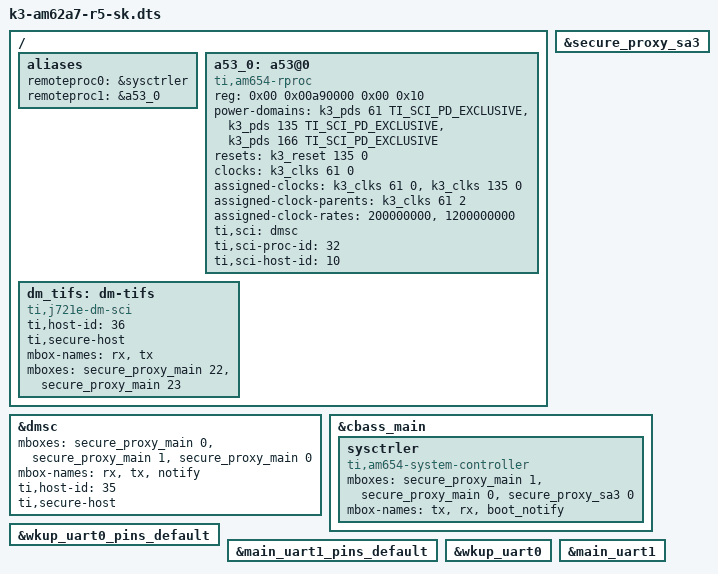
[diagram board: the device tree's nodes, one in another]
// SPDX-License-Identifier: GPL-2.0
/*
 * AM62A7 SK dts file for R5 SPL
 * Copyright (C) 2022 Texas Instruments Incorporated - https://www.ti.com/
 */

#include "k3-am62a7-sk.dts"
#include "k3-am62a-ddr-1866mhz-32bit.dtsi"
#include "k3-am62a-ddr.dtsi"

#include "k3-am62a7-sk-u-boot.dtsi"

/ {
	aliases {
		remoteproc0 = &sysctrler;
		remoteproc1 = &a53_0;
	};

	a53_0: a53@0 {
		compatible = "ti,am654-rproc";
		reg = <0x00 0x00a90000 0x00 0x10>;
		power-domains = <&k3_pds 61 TI_SCI_PD_EXCLUSIVE>,
				<&k3_pds 135 TI_SCI_PD_EXCLUSIVE>,
				<&k3_pds 166 TI_SCI_PD_EXCLUSIVE>;
		resets = <&k3_reset 135 0>;
		clocks = <&k3_clks 61 0>;
		assigned-clocks = <&k3_clks 61 0>, <&k3_clks 135 0>;
		assigned-clock-parents = <&k3_clks 61 2>;
		assigned-clock-rates = <200000000>, <1200000000>;
		ti,sci = <&dmsc>;
		ti,sci-proc-id = <32>;
		ti,sci-host-id = <10>;
		bootph-pre-ram;
	};

	dm_tifs: dm-tifs {
		compatible = "ti,j721e-dm-sci";
		ti,host-id = <36>;
		ti,secure-host;
		mbox-names = "rx", "tx";
		mboxes= <&secure_proxy_main 22>,
			<&secure_proxy_main 23>;
		bootph-pre-ram;
	};
};

&dmsc {
	mboxes= <&secure_proxy_main 0>,
		<&secure_proxy_main 1>,
		<&secure_proxy_main 0>;
	mbox-names = "rx", "tx", "notify";
	ti,host-id = <35>;
	ti,secure-host;
};

&secure_proxy_sa3 {
	/* Needed for initial handshake with ROM */
	status = "okay";
	bootph-pre-ram;
};

&cbass_main {
	sysctrler: sysctrler {
		compatible = "ti,am654-system-controller";
		mboxes= <&secure_proxy_main 1>,
			<&secure_proxy_main 0>,
			<&secure_proxy_sa3 0>;
		mbox-names = "tx", "rx", "boot_notify";
		bootph-pre-ram;
	};
};

&wkup_uart0_pins_default {
	bootph-pre-ram;
};

&main_uart1_pins_default {
	bootph-pre-ram;
};

/* WKUP UART0 is used for DM firmware logs */
&wkup_uart0 {
	status = "okay";
	bootph-pre-ram;
};

/* Main UART1 is used for TIFS firmware logs */
&main_uart1 {
	status = "okay";
	bootph-pre-ram;
};
